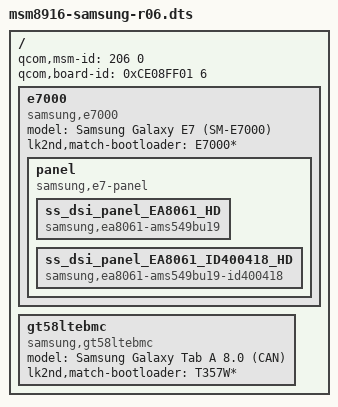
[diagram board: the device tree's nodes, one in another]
// SPDX-License-Identifier: GPL-2.0-only

/dts-v1/;

#include <skeleton.dtsi>

/ {
	// This is used by the bootloader to find the correct DTB
	qcom,msm-id = <206 0>;
	qcom,board-id = <0xCE08FF01 6>;

	e7000 {
		model = "Samsung Galaxy E7 (SM-E7000)";
		compatible = "samsung,e7000", "qcom,msm8916", "lk2nd,device";
		lk2nd,match-bootloader = "E7000*";

		panel {
			compatible = "samsung,e7-panel";

			ss_dsi_panel_EA8061_HD {
				compatible = "samsung,ea8061-ams549bu19";
			};
			ss_dsi_panel_EA8061_ID400418_HD {
				compatible = "samsung,ea8061-ams549bu19-id400418";
			};
		};
	};

	gt58ltebmc {
		model = "Samsung Galaxy Tab A 8.0 (CAN)";
		compatible = "samsung,gt58ltebmc", "qcom,msm8916", "lk2nd,device";
		lk2nd,match-bootloader = "T357W*";
	};
};
